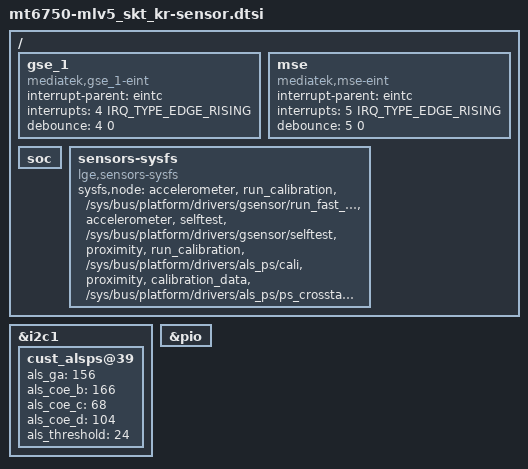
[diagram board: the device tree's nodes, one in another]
/*
 * LG Electronics LV5 sensor device tree source
 *
 * Copyright (c) 2016 LG Electronics Co., Ltd.
 *              http://www.lge.com
 *
 */


/ {
	/delete-node/ gyro;

	/delete-node/ cust_accel@0;
	/delete-node/ cust_alsps@0;
	/delete-node/ cust_baro@0;
	/delete-node/ cust_gyro@0;
	/delete-node/ cust_mag@0;

	gse_1 {
		compatible = "mediatek,gse_1-eint";
		interrupt-parent = <&eintc>;
		interrupts = <4 IRQ_TYPE_EDGE_RISING>;
		debounce = <4 0>;
		status = "okay";
	};

	mse {
		compatible = "mediatek,mse-eint";
		interrupt-parent = <&eintc>;
		interrupts = <5 IRQ_TYPE_EDGE_RISING>;
		debounce = <5 0>;
		status = "okay";
	};

	soc {
		/delete-node/ als_ps@0;
		/delete-node/ barometer@0;
		/delete-node/ gsensor@0;
		/delete-node/ gyroscope@0;
		/delete-node/ msensor@0;
	};

/*sysfs node for unified usercal*/
	sensors-sysfs {
		compatible = "lge,sensors-sysfs";
		sysfs,node =
			/* group, user_node, kernel node */
			"accelerometer", "run_calibration",  "/sys/bus/platform/drivers/gsensor/run_fast_calibration",
			"accelerometer", "selftest",         "/sys/bus/platform/drivers/gsensor/selftest",
//			"gyroscope",     "run_calibration",  "/sys/bus/platform/drivers/gyroscope/run_fast_calibration",
//			"gyroscope",     "selftest",         "/sys/bus/platform/drivers/gyroscope/selftest",
			"proximity",     "run_calibration",  "/sys/bus/platform/drivers/als_ps/cali",
			"proximity",     "calibration_data", "/sys/bus/platform/drivers/als_ps/ps_crosstalk"
			;
	};
};

/* sensor i2c start */
&i2c1 {
	/delete-node/ alsps@60;
	/delete-node/ gsensor@68;
	/delete-node/ gyro@68;
	/delete-node/ msensor@0f;

	#include "../k303b-acc.dtsi"
	#include "../k303b-mag.dtsi"
	#include "../apds9930.dtsi"

	cust_alsps@39 {
		als_ga = <156>;
		als_coe_b = <166>;
		als_coe_c = <68>;
		als_coe_d = <104>;
		als_threshold = <24>; // ch0 data for 8lux
	};
// move direction to rev dts
};
/* sensor i2c end */

/* sensor gpio start */
&pio {

};
/* sensor gpio end */
